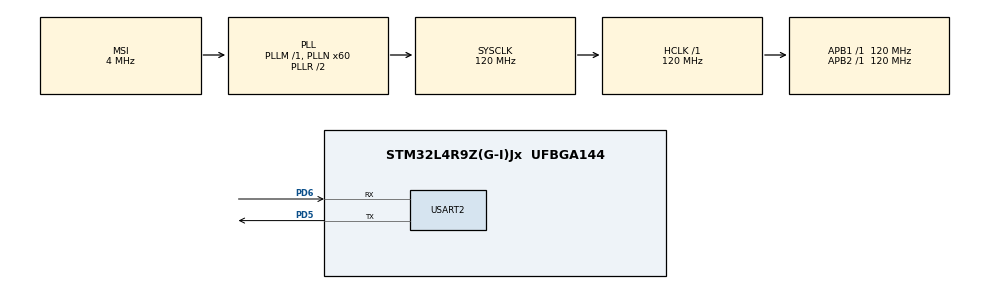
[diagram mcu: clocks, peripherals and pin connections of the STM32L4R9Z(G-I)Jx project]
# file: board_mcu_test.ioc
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Mcu.Family=STM32L4
Mcu.Name=STM32L4R9Z(G-I)Jx
Mcu.Package=UFBGA144
NVIC.PriorityGroup=NVIC_PRIORITYGROUP_4
PD5.Mode=Asynchronous
PD5.Signal=USART2_TX
PD6.Mode=Asynchronous
PD6.Signal=USART2_RX
ProjectManager.HeapSize=0x200
ProjectManager.StackSize=0x400
ProjectManager.TargetToolchain=STM32CubeIDE
RCC.AHBFreq_Value=120000000
RCC.APB1Freq_Value=120000000
RCC.APB1TimFreq_Value=120000000
RCC.APB2Freq_Value=120000000
RCC.APB2TimFreq_Value=120000000
RCC.CortexFreq_Value=120000000
RCC.HCLKFreq_Value=120000000
RCC.HSE_VALUE=8000000
RCC.HSI48_VALUE=48000000
RCC.HSI_VALUE=16000000
RCC.LSE_VALUE=32768
RCC.MSI_VALUE=4000000
RCC.PLLN=60
RCC.SYSCLKFreq_VALUE=120000000
RCC.SYSCLKSource=RCC_SYSCLKSOURCE_PLLCLK
RCC.VCOOutputFreq_Value=240000000
USART2.VirtualMode-Asynchronous=VM_ASYNC
board=custom

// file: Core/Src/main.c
/* USER CODE BEGIN Header */
/**
  ******************************************************************************
  * @file           : main.c
  * @brief          : Main program body
  ******************************************************************************
  * @attention
  *
  * Copyright (c) 2023 STMicroelectronics.
  * All rights reserved.
  *
  * This software is licensed under terms that can be found in the LICENSE file
  * in the root directory of this software component.
  * If no LICENSE file comes with this software, it is provided AS-IS.
  *
  ******************************************************************************
  */
/* USER CODE END Header */
#include "main.h"

/* USER CODE BEGIN Includes */
#include <stdio.h>

#include "STWIN.h"
#include "retarget.h"
#include "STWIN_env_sensors.h"
/* USER CODE END Includes */

/* USER CODE BEGIN PD */
#define HTS221_ODR 12.5f /* ODR = 12.5Hz */
#define LPS22HH_ODR 50.0f /* ODR = 50.0Hz */
#define STTS751_ODR 16.0f /* ODR = 16.0Hz */
/* USER CODE END PD */

UART_HandleTypeDef huart2;

/* USER CODE BEGIN PV */
SD_HandleTypeDef hsd1;
/* USER CODE END PV */

void SystemClock_Config(void);
static void MX_GPIO_Init(void);
static void MX_USART2_UART_Init(void);

int main(void)
{
  /* USER CODE BEGIN 1 */
  uint32_t status = 0;
  float temp = 0;
  float humidity = 0;
  float pressure = 0;
  /* USER CODE END 1 */

  /* MCU Configuration--------------------------------------------------------*/

  /* Reset of all peripherals, Initializes the Flash interface and the Systick. */
  HAL_Init();

  /* Configure the system clock */
  SystemClock_Config();

  /* Initialize all configured peripherals */
  MX_GPIO_Init();
  MX_USART2_UART_Init();
  /* USER CODE BEGIN 2 */
  BSP_LED_Init(LED1);
  BSP_LED_Init(LED2);

  // Init printf redirect
  RetargetInit(&huart2);

  do {

	  status = BSP_ENV_SENSOR_Init(STTS751_0, ENV_TEMPERATURE);
	  if(status) {
		  printf("Error Initializing STTS751 Temperature Sensor.\r\n");
		  break;
	  }

	  BSP_ENV_SENSOR_SetOutputDataRate(STTS751_0, ENV_TEMPERATURE, STTS751_ODR);
	  status = BSP_ENV_SENSOR_Enable(STTS751_0, ENV_TEMPERATURE);
	  if(status) {
		  printf("Error Enabling STTS751 Temperature Sensor.\r\n");
		  break;
	  }

	  BSP_ENV_SENSOR_Init(LPS22HH_0, ENV_PRESSURE);
	  if(status) {
		  printf("Error Initializing LPS22HH Pressure Sensor.\r\n");
		  break;
	  }

	  BSP_ENV_SENSOR_SetOutputDataRate(LPS22HH_0, ENV_PRESSURE, LPS22HH_ODR);

	  BSP_ENV_SENSOR_Enable(LPS22HH_0, ENV_PRESSURE);
	  if(status) {
		  printf("Error Enabling LPS22HH Pressure Sensor.\r\n");
		  break;
	  }

	  status = BSP_ENV_SENSOR_Init(HTS221_0, ENV_HUMIDITY);
	  if(status) {
		  printf("Error Initializing HTS221 Temperature/Pressure Sensor.\r\n");
		  break;
	  }

	  BSP_ENV_SENSOR_SetOutputDataRate(HTS221_0, ENV_HUMIDITY, HTS221_ODR);
	  status = BSP_ENV_SENSOR_Enable(HTS221_0, ENV_HUMIDITY);
	  if(status) {
		  printf("Error Enabling HTS221 Temperature/Pressure Sensor.\r\n");
		  break;
	  }
  } while(0);

  /* USER CODE END 2 */

  /* Infinite loop */
  /* USER CODE BEGIN WHILE */
  while (1)
  {

	  status = BSP_ENV_SENSOR_GetValue(STTS751_0, ENV_TEMPERATURE, &temp);
	  if(status)
		  printf("Error Getting Temperature Values (STTS751).\r\n");
	  else
		  printf("Current Temperature: %.2f C\r\n", temp);

	  status = BSP_ENV_SENSOR_GetValue(LPS22HH_0, ENV_PRESSURE, &pressure);
	  if(status)
		  printf("Error Getting Pressure Values (LPS22HH).\r\n");
	  else
		  printf("Current Pressure: %f hPa\r\n", pressure);

	  status = BSP_ENV_SENSOR_GetValue(HTS221_0, ENV_HUMIDITY, &humidity);
	  if(status)
		  printf("Error Getting Humidity Values (HTS221).\r\n");
	  else
		  printf("Current Humidity: %f%%\r\n", humidity);

	  BSP_LED_Toggle(LED1);
	  HAL_Delay(900);
	  BSP_LED_Toggle(LED2);
	  HAL_Delay(100);
    /* USER CODE END WHILE */

  }
}

void SystemClock_Config(void)
{
  RCC_OscInitTypeDef RCC_OscInitStruct = {0};
  RCC_ClkInitTypeDef RCC_ClkInitStruct = {0};

  /** Configure the main internal regulator output voltage
  */
  if (HAL_PWREx_ControlVoltageScaling(PWR_REGULATOR_VOLTAGE_SCALE1_BOOST) != HAL_OK)
  {
    Error_Handler();
  }

  /** Initializes the RCC Oscillators according to the specified parameters
  * in the RCC_OscInitTypeDef structure.
  */
  RCC_OscInitStruct.OscillatorType = RCC_OSCILLATORTYPE_MSI;
  RCC_OscInitStruct.MSIState = RCC_MSI_ON;
  RCC_OscInitStruct.MSICalibrationValue = 0;
  RCC_OscInitStruct.MSIClockRange = RCC_MSIRANGE_6;
  RCC_OscInitStruct.PLL.PLLState = RCC_PLL_ON;
  RCC_OscInitStruct.PLL.PLLSource = RCC_PLLSOURCE_MSI;
  RCC_OscInitStruct.PLL.PLLM = 1;
  RCC_OscInitStruct.PLL.PLLN = 60;
  RCC_OscInitStruct.PLL.PLLP = RCC_PLLP_DIV2;
  RCC_OscInitStruct.PLL.PLLQ = RCC_PLLQ_DIV2;
  RCC_OscInitStruct.PLL.PLLR = RCC_PLLR_DIV2;
  if (HAL_RCC_OscConfig(&RCC_OscInitStruct) != HAL_OK)
  {
    Error_Handler();
  }

  /** Initializes the CPU, AHB and APB buses clocks
  */
  RCC_ClkInitStruct.ClockType = RCC_CLOCKTYPE_HCLK|RCC_CLOCKTYPE_SYSCLK
                              |RCC_CLOCKTYPE_PCLK1|RCC_CLOCKTYPE_PCLK2;
  RCC_ClkInitStruct.SYSCLKSource = RCC_SYSCLKSOURCE_PLLCLK;
  RCC_ClkInitStruct.AHBCLKDivider = RCC_SYSCLK_DIV1;
  RCC_ClkInitStruct.APB1CLKDivider = RCC_HCLK_DIV1;
  RCC_ClkInitStruct.APB2CLKDivider = RCC_HCLK_DIV1;

  if (HAL_RCC_ClockConfig(&RCC_ClkInitStruct, FLASH_LATENCY_5) != HAL_OK)
  {
    Error_Handler();
  }
}

static void MX_USART2_UART_Init(void)
{

  huart2.Instance = USART2;
  huart2.Init.BaudRate = 115200;
  huart2.Init.WordLength = UART_WORDLENGTH_8B;
  huart2.Init.StopBits = UART_STOPBITS_1;
  huart2.Init.Parity = UART_PARITY_NONE;
  huart2.Init.Mode = UART_MODE_TX_RX;
  huart2.Init.HwFlowCtl = UART_HWCONTROL_NONE;
  huart2.Init.OverSampling = UART_OVERSAMPLING_16;
  huart2.Init.OneBitSampling = UART_ONE_BIT_SAMPLE_DISABLE;
  huart2.Init.ClockPrescaler = UART_PRESCALER_DIV1;
  huart2.AdvancedInit.AdvFeatureInit = UART_ADVFEATURE_NO_INIT;
  if (HAL_UART_Init(&huart2) != HAL_OK)
  {
    Error_Handler();
  }
  if (HAL_UARTEx_SetTxFifoThreshold(&huart2, UART_TXFIFO_THRESHOLD_1_8) != HAL_OK)
  {
    Error_Handler();
  }
  if (HAL_UARTEx_SetRxFifoThreshold(&huart2, UART_RXFIFO_THRESHOLD_1_8) != HAL_OK)
  {
    Error_Handler();
  }
  if (HAL_UARTEx_DisableFifoMode(&huart2) != HAL_OK)
  {
    Error_Handler();
  }

}

static void MX_GPIO_Init(void)
{

  /* GPIO Ports Clock Enable */
  __HAL_RCC_GPIOD_CLK_ENABLE();

}

void Error_Handler(void)
{
  __disable_irq();
  while (1)
  {
  }
}
